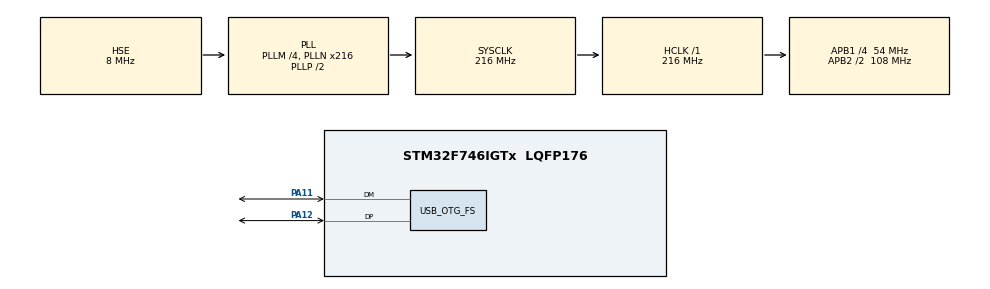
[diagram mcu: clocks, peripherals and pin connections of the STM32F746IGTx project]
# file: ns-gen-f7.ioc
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CORTEX_M7.default_mode_Activation=1
Mcu.Family=STM32F7
Mcu.Name=STM32F746IGTx
Mcu.Package=LQFP176
NVIC.OTG_FS_IRQn=true\:0\:0\:false\:false\:true\:true\:true\:true
NVIC.PriorityGroup=NVIC_PRIORITYGROUP_4
PA11.Mode=Device_Only
PA11.Signal=USB_OTG_FS_DM
PA12.Mode=Device_Only
PA12.Signal=USB_OTG_FS_DP
PH0/OSC_IN.Mode=HSE-External-Oscillator
PH0/OSC_IN.Signal=RCC_OSC_IN
PH1/OSC_OUT.Mode=HSE-External-Oscillator
PH1/OSC_OUT.Signal=RCC_OSC_OUT
ProjectManager.HeapSize=0x200
ProjectManager.StackSize=0x400
ProjectManager.TargetToolchain=STM32CubeIDE
RCC.AHBFreq_Value=216000000
RCC.APB1CLKDivider=RCC_HCLK_DIV4
RCC.APB1Freq_Value=54000000
RCC.APB1TimFreq_Value=108000000
RCC.APB2CLKDivider=RCC_HCLK_DIV2
RCC.APB2Freq_Value=108000000
RCC.APB2TimFreq_Value=216000000
RCC.CortexFreq_Value=216000000
RCC.HCLKFreq_Value=216000000
RCC.HSE_VALUE=8000000
RCC.HSI_VALUE=16000000
RCC.LSE_VALUE=32768
RCC.PLLM=4
RCC.PLLN=216
RCC.PLLQ=9
RCC.SYSCLKFreq_VALUE=216000000
RCC.SYSCLKSource=RCC_SYSCLKSOURCE_PLLCLK
RCC.USBFreq_Value=48000000
RCC.VCOOutputFreq_Value=432000000
USB_OTG_FS.VirtualMode=Device_Only
board=custom

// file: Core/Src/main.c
/* USER CODE BEGIN Header */
/**
  ******************************************************************************
  * @file           : main.c
  * @brief          : Main program body
  ******************************************************************************
  * @attention
  *
  * Copyright (c) 2026 STMicroelectronics.
  * All rights reserved.
  *
  * This software is licensed under terms that can be found in the LICENSE file
  * in the root directory of this software component.
  * If no LICENSE file comes with this software, it is provided AS-IS.
  *
  ******************************************************************************
  */
/* USER CODE END Header */
#include "main.h"
#include "usb_otg.h"
#include "gpio.h"

/* USER CODE BEGIN Includes */
#include "SEGGER_RTT.h"

/* USER CODE END Includes */

/* USER CODE BEGIN PTD */
#define dbg(s)                        SEGGER_RTT_WriteString( 0, s )//; HAL_Delay(1)
#define dbgln(s)                      dbg( s "\n" )
#define dbgf( format, ... )           SEGGER_RTT_printf( 0, ( const char * ) ( format ), ##__VA_ARGS__ ); HAL_Delay(1)
/* USER CODE END PTD */

void SystemClock_Config(void);
static void MPU_Config(void);
/* USER CODE BEGIN PFP */
void init(void){
	SEGGER_RTT_ConfigUpBuffer( 0, NULL, NULL, 0, SEGGER_RTT_MODE_NO_BLOCK_TRIM );
    SEGGER_RTT_WriteString( 0, "SEGGER Real-Time-Terminal Sample\n" );
}
/* USER CODE END PFP */

int main(void)
{

  /* USER CODE BEGIN 1 */
	init();
  /* USER CODE END 1 */

  /* MPU Configuration--------------------------------------------------------*/
  MPU_Config();

  /* MCU Configuration--------------------------------------------------------*/

  /* Reset of all peripherals, Initializes the Flash interface and the Systick. */
  HAL_Init();

  /* Configure the system clock */
  SystemClock_Config();

  /* Initialize all configured peripherals */
  MX_GPIO_Init();
  MX_USB_OTG_FS_PCD_Init();
  /* USER CODE BEGIN 2 */
  dbgln("Init Finish \n\r Program started");
  /* USER CODE END 2 */

  /* Infinite loop */
  while (1)
  {

    /* USER CODE BEGIN 3 */
	  HAL_Delay(1000);
	  dbgln("from loop");
  }
  /* USER CODE END 3 */
}

void SystemClock_Config(void)
{
  RCC_OscInitTypeDef RCC_OscInitStruct = {0};
  RCC_ClkInitTypeDef RCC_ClkInitStruct = {0};

  /** Configure the main internal regulator output voltage
  */
  __HAL_RCC_PWR_CLK_ENABLE();
  __HAL_PWR_VOLTAGESCALING_CONFIG(PWR_REGULATOR_VOLTAGE_SCALE1);

  /** Initializes the RCC Oscillators according to the specified parameters
  * in the RCC_OscInitTypeDef structure.
  */
  RCC_OscInitStruct.OscillatorType = RCC_OSCILLATORTYPE_HSE;
  RCC_OscInitStruct.HSEState = RCC_HSE_ON;
  RCC_OscInitStruct.PLL.PLLState = RCC_PLL_ON;
  RCC_OscInitStruct.PLL.PLLSource = RCC_PLLSOURCE_HSE;
  RCC_OscInitStruct.PLL.PLLM = 4;
  RCC_OscInitStruct.PLL.PLLN = 216;
  RCC_OscInitStruct.PLL.PLLP = RCC_PLLP_DIV2;
  RCC_OscInitStruct.PLL.PLLQ = 9;
  if (HAL_RCC_OscConfig(&RCC_OscInitStruct) != HAL_OK)
  {
    Error_Handler();
  }

  /** Activate the Over-Drive mode
  */
  if (HAL_PWREx_EnableOverDrive() != HAL_OK)
  {
    Error_Handler();
  }

  /** Initializes the CPU, AHB and APB buses clocks
  */
  RCC_ClkInitStruct.ClockType = RCC_CLOCKTYPE_HCLK|RCC_CLOCKTYPE_SYSCLK
                              |RCC_CLOCKTYPE_PCLK1|RCC_CLOCKTYPE_PCLK2;
  RCC_ClkInitStruct.SYSCLKSource = RCC_SYSCLKSOURCE_PLLCLK;
  RCC_ClkInitStruct.AHBCLKDivider = RCC_SYSCLK_DIV1;
  RCC_ClkInitStruct.APB1CLKDivider = RCC_HCLK_DIV4;
  RCC_ClkInitStruct.APB2CLKDivider = RCC_HCLK_DIV2;

  if (HAL_RCC_ClockConfig(&RCC_ClkInitStruct, FLASH_LATENCY_7) != HAL_OK)
  {
    Error_Handler();
  }
}

 /* MPU Configuration */

void MPU_Config(void)
{
  MPU_Region_InitTypeDef MPU_InitStruct = {0};

  /* Disables the MPU */
  HAL_MPU_Disable();

  /** Initializes and configures the Region and the memory to be protected
  */
  MPU_InitStruct.Enable = MPU_REGION_ENABLE;
  MPU_InitStruct.Number = MPU_REGION_NUMBER0;
  MPU_InitStruct.BaseAddress = 0x0;
  MPU_InitStruct.Size = MPU_REGION_SIZE_4GB;
  MPU_InitStruct.SubRegionDisable = 0x87;
  MPU_InitStruct.TypeExtField = MPU_TEX_LEVEL0;
  MPU_InitStruct.AccessPermission = MPU_REGION_NO_ACCESS;
  MPU_InitStruct.DisableExec = MPU_INSTRUCTION_ACCESS_DISABLE;
  MPU_InitStruct.IsShareable = MPU_ACCESS_SHAREABLE;
  MPU_InitStruct.IsCacheable = MPU_ACCESS_NOT_CACHEABLE;
  MPU_InitStruct.IsBufferable = MPU_ACCESS_NOT_BUFFERABLE;

  HAL_MPU_ConfigRegion(&MPU_InitStruct);
  /* Enables the MPU */
  HAL_MPU_Enable(MPU_PRIVILEGED_DEFAULT);

}

void Error_Handler(void)
{
  __disable_irq();
  while (1)
  {
  }
}
